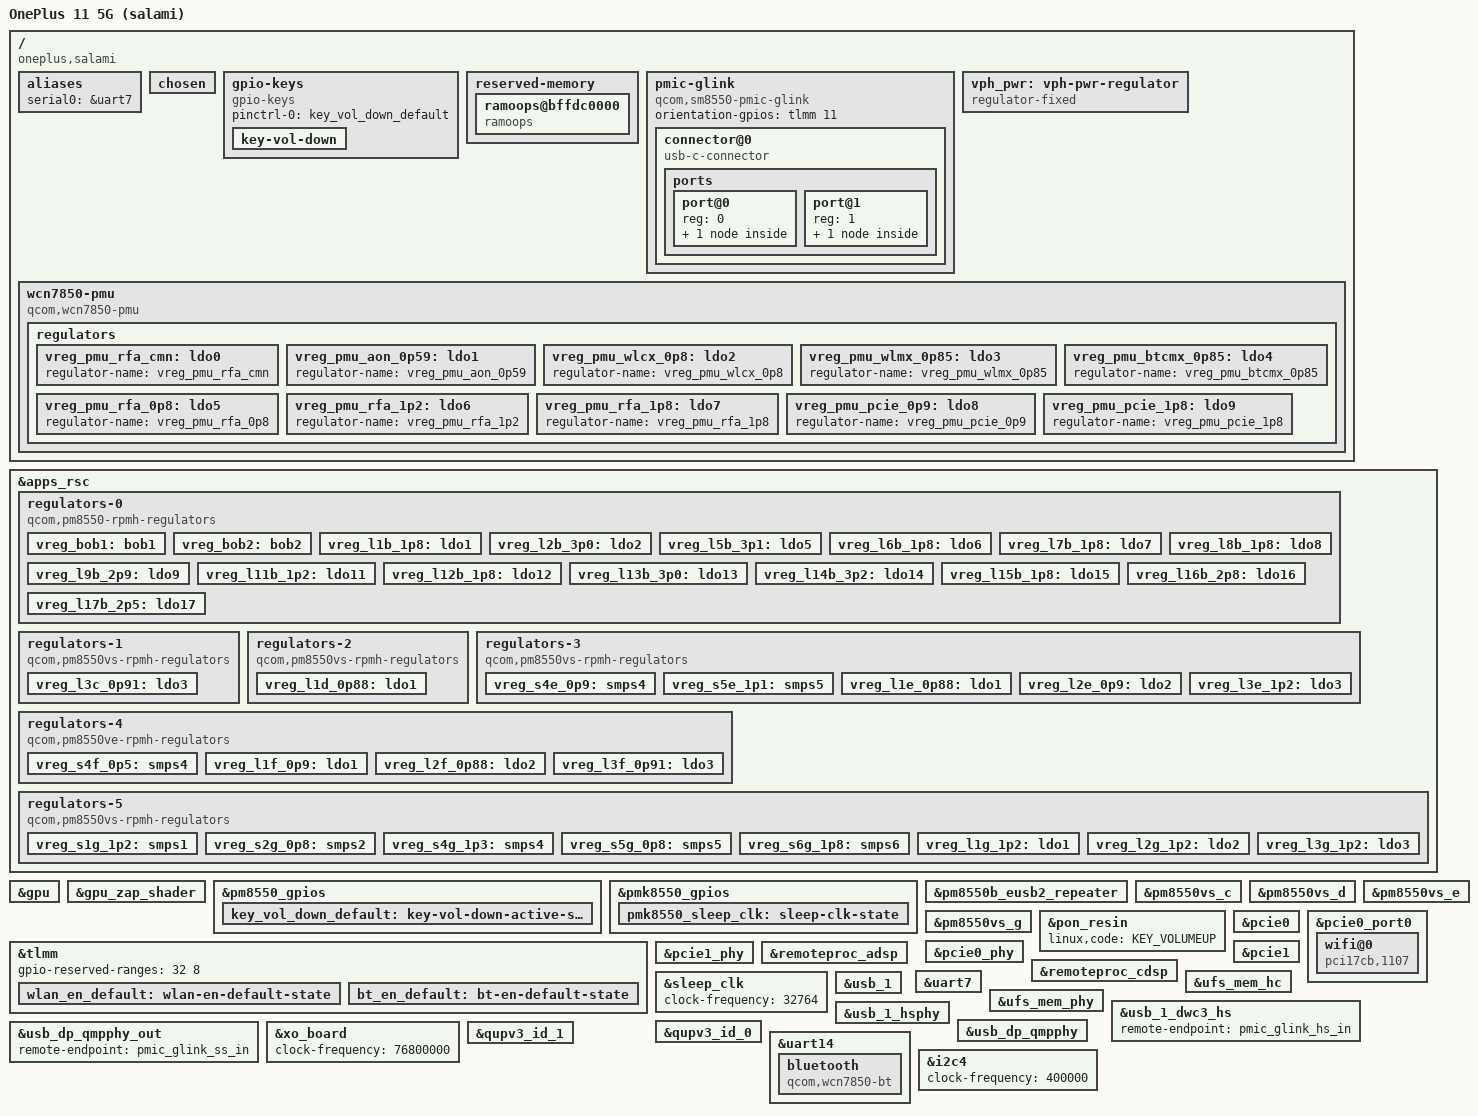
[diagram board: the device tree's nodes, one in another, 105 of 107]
// SPDX-License-Identifier: BSD-3-Clause
/*
 * OnePlus 11 5G (PHB110, codename salami, Qualcomm SM8550/Kalama).
 *
 * Mainline bring-up DTS, modelled after sm8550-mtp.dts with device facts
 * taken from the downstream OnePlus devicetree:
 *   panel   samsung AMB670YF07 CS (reset = TLMM 133)  -- panel driver pending
 *   touch   synaptics S3908 @ i2c4 0x4b (irq TLMM 25, reset TLMM 24) -- pending
 *   vol key PM8550 GPIO6, resin = PMK8550
 */

/dts-v1/;

#include <dt-bindings/input/linux-event-codes.h>
#include <dt-bindings/regulator/qcom,rpmh-regulator.h>
#include "sm8550.dtsi"
#include "pm8550.dtsi"
#include "pm8550b.dtsi"
#define PMK8550VE_SID 5
#include "pm8550ve.dtsi"
#include "pm8550vs.dtsi"
#include "pmk8550.dtsi"

/ {
	model = "OnePlus 11 5G (salami)";
	compatible = "oneplus,salami", "qcom,sm8550";
	chassis-type = "handset";

	qcom,msm-id = <519 0x10000>, <536 0x10000>, <519 0x20000>, <536 0x20000>;
	qcom,board-id = <0x10008 0>;

	aliases {
		serial0 = &uart7;
	};

	chosen {
		stdout-path = "serial0:115200n8";
		bootargs = "earlycon=msm_geni_serial,0x0a9c0000 console=ttyMSM0,115200n8 loglevel=7 keep_bootcon panic=10";
	};

	gpio-keys {
		compatible = "gpio-keys";

		pinctrl-names = "default";
		pinctrl-0 = <&key_vol_down_default>;

		key-vol-down {
			label = "Volume down";
			gpios = <&pm8550_gpios 6 GPIO_ACTIVE_LOW>;
			linux,code = <KEY_VOLUMEDOWN>;
			debounce-interval = <15>;
			wakeup-source;
		};
	};

	reserved-memory {
		/* fixed-address bring-up ramoops: console survives a watchdog/long-press
		 * reboot so it can be read back from /sys/fs/pstore by the stock system */
		ramoops@bffdc0000 {
			compatible = "ramoops";
			reg = <0xb 0xffdc0000 0x0 0x240000>;
			console-size = <0x40000>;
			pmsg-size = <0x200000>;
			no-map;
		};
	};

	pmic-glink {
		compatible = "qcom,sm8550-pmic-glink", "qcom,pmic-glink";
		#address-cells = <1>;
		#size-cells = <0>;
		orientation-gpios = <&tlmm 11 GPIO_ACTIVE_HIGH>;

		connector@0 {
			compatible = "usb-c-connector";
			reg = <0>;
			power-role = "dual";
			data-role = "dual";

			ports {
				#address-cells = <1>;
				#size-cells = <0>;

				port@0 {
					reg = <0>;

					pmic_glink_hs_in: endpoint {
						remote-endpoint = <&usb_1_dwc3_hs>;
					};
				};

				port@1 {
					reg = <1>;

					pmic_glink_ss_in: endpoint {
						remote-endpoint = <&usb_dp_qmpphy_out>;
					};
				};
			};
		};
	};

	vph_pwr: vph-pwr-regulator {
		compatible = "regulator-fixed";
		regulator-name = "vph_pwr";
		regulator-min-microvolt = <3700000>;
		regulator-max-microvolt = <3700000>;

		regulator-always-on;
		regulator-boot-on;
	};

	/* WCN7850 (kiwi) WLAN/BT power sequencing; wlan-en = TLMM 80, bt-en = TLMM 81 */
	wcn7850-pmu {
		compatible = "qcom,wcn7850-pmu";

		pinctrl-names = "default";
		pinctrl-0 = <&wlan_en_default>, <&bt_en_default>, <&pmk8550_sleep_clk>;

		wlan-enable-gpios = <&tlmm 80 GPIO_ACTIVE_HIGH>;
		bt-enable-gpios = <&tlmm 81 GPIO_ACTIVE_HIGH>;

		vdd-supply = <&vreg_s5g_0p8>;
		vddio-supply = <&vreg_l15b_1p8>;
		vddio1p2-supply = <&vreg_l3e_1p2>;
		vddaon-supply = <&vreg_s2g_0p8>;
		vdddig-supply = <&vreg_s4e_0p9>;
		vddrfa1p2-supply = <&vreg_s4g_1p3>;
		vddrfa1p8-supply = <&vreg_s6g_1p8>;

		regulators {
			vreg_pmu_rfa_cmn: ldo0 {
				regulator-name = "vreg_pmu_rfa_cmn";
			};

			vreg_pmu_aon_0p59: ldo1 {
				regulator-name = "vreg_pmu_aon_0p59";
			};

			vreg_pmu_wlcx_0p8: ldo2 {
				regulator-name = "vreg_pmu_wlcx_0p8";
			};

			vreg_pmu_wlmx_0p85: ldo3 {
				regulator-name = "vreg_pmu_wlmx_0p85";
			};

			vreg_pmu_btcmx_0p85: ldo4 {
				regulator-name = "vreg_pmu_btcmx_0p85";
			};

			vreg_pmu_rfa_0p8: ldo5 {
				regulator-name = "vreg_pmu_rfa_0p8";
			};

			vreg_pmu_rfa_1p2: ldo6 {
				regulator-name = "vreg_pmu_rfa_1p2";
			};

			vreg_pmu_rfa_1p8: ldo7 {
				regulator-name = "vreg_pmu_rfa_1p8";
			};

			vreg_pmu_pcie_0p9: ldo8 {
				regulator-name = "vreg_pmu_pcie_0p9";
			};

			vreg_pmu_pcie_1p8: ldo9 {
				regulator-name = "vreg_pmu_pcie_1p8";
			};
		};
	};
};

&apps_rsc {
	regulators-0 {
		compatible = "qcom,pm8550-rpmh-regulators";
		qcom,pmic-id = "b";

		vdd-bob1-supply = <&vph_pwr>;
		vdd-bob2-supply = <&vph_pwr>;
		vdd-l1-l4-l10-supply = <&vreg_s6g_1p8>;
		vdd-l2-l13-l14-supply = <&vreg_bob1>;
		vdd-l3-supply = <&vreg_s4g_1p3>;
		vdd-l5-l16-supply = <&vreg_bob1>;
		vdd-l6-l7-supply = <&vreg_bob1>;
		vdd-l8-l9-supply = <&vreg_bob1>;
		vdd-l11-supply = <&vreg_s4g_1p3>;
		vdd-l12-supply = <&vreg_s6g_1p8>;
		vdd-l15-supply = <&vreg_s6g_1p8>;
		vdd-l17-supply = <&vreg_bob2>;

		vreg_bob1: bob1 {
			regulator-name = "vreg_bob1";
			regulator-min-microvolt = <3296000>;
			regulator-max-microvolt = <3960000>;
			regulator-initial-mode = <RPMH_REGULATOR_MODE_HPM>;
		};

		vreg_bob2: bob2 {
			regulator-name = "vreg_bob2";
			regulator-min-microvolt = <2720000>;
			regulator-max-microvolt = <3960000>;
			regulator-initial-mode = <RPMH_REGULATOR_MODE_HPM>;
		};

		vreg_l1b_1p8: ldo1 {
			regulator-name = "vreg_l1b_1p8";
			regulator-min-microvolt = <1800000>;
			regulator-max-microvolt = <1800000>;
			regulator-initial-mode = <RPMH_REGULATOR_MODE_HPM>;
		};

		vreg_l2b_3p0: ldo2 {
			regulator-name = "vreg_l2b_3p0";
			regulator-min-microvolt = <3008000>;
			regulator-max-microvolt = <3008000>;
			regulator-initial-mode = <RPMH_REGULATOR_MODE_HPM>;
		};

		vreg_l5b_3p1: ldo5 {
			regulator-name = "vreg_l5b_3p1";
			regulator-min-microvolt = <3104000>;
			regulator-max-microvolt = <3104000>;
			regulator-initial-mode = <RPMH_REGULATOR_MODE_HPM>;
		};

		vreg_l6b_1p8: ldo6 {
			regulator-name = "vreg_l6b_1p8";
			regulator-min-microvolt = <1800000>;
			regulator-max-microvolt = <3008000>;
			regulator-initial-mode = <RPMH_REGULATOR_MODE_HPM>;
		};

		vreg_l7b_1p8: ldo7 {
			regulator-name = "vreg_l7b_1p8";
			regulator-min-microvolt = <1800000>;
			regulator-max-microvolt = <3008000>;
			regulator-initial-mode = <RPMH_REGULATOR_MODE_HPM>;
		};

		vreg_l8b_1p8: ldo8 {
			regulator-name = "vreg_l8b_1p8";
			regulator-min-microvolt = <1800000>;
			regulator-max-microvolt = <3008000>;
			regulator-initial-mode = <RPMH_REGULATOR_MODE_HPM>;
		};

		vreg_l9b_2p9: ldo9 {
			regulator-name = "vreg_l9b_2p9";
			regulator-min-microvolt = <2960000>;
			regulator-max-microvolt = <3008000>;
			regulator-initial-mode = <RPMH_REGULATOR_MODE_HPM>;
		};

		vreg_l11b_1p2: ldo11 {
			regulator-name = "vreg_l11b_1p2";
			regulator-min-microvolt = <1200000>;
			regulator-max-microvolt = <1504000>;
			regulator-initial-mode = <RPMH_REGULATOR_MODE_HPM>;
		};

		vreg_l12b_1p8: ldo12 {
			regulator-name = "vreg_l12b_1p8";
			regulator-min-microvolt = <1800000>;
			regulator-max-microvolt = <1800000>;
			regulator-initial-mode = <RPMH_REGULATOR_MODE_HPM>;
		};

		vreg_l13b_3p0: ldo13 {
			regulator-name = "vreg_l13b_3p0";
			regulator-min-microvolt = <3000000>;
			regulator-max-microvolt = <3000000>;
			regulator-initial-mode = <RPMH_REGULATOR_MODE_HPM>;
		};

		vreg_l14b_3p2: ldo14 {
			regulator-name = "vreg_l14b_3p2";
			regulator-min-microvolt = <3200000>;
			regulator-max-microvolt = <3200000>;
			regulator-initial-mode = <RPMH_REGULATOR_MODE_HPM>;
		};

		vreg_l15b_1p8: ldo15 {
			regulator-name = "vreg_l15b_1p8";
			regulator-min-microvolt = <1800000>;
			regulator-max-microvolt = <1800000>;
			regulator-initial-mode = <RPMH_REGULATOR_MODE_HPM>;
		};

		vreg_l16b_2p8: ldo16 {
			regulator-name = "vreg_l16b_2p8";
			regulator-min-microvolt = <2800000>;
			regulator-max-microvolt = <2800000>;
			regulator-initial-mode = <RPMH_REGULATOR_MODE_HPM>;
		};

		vreg_l17b_2p5: ldo17 {
			regulator-name = "vreg_l17b_2p5";
			regulator-min-microvolt = <2504000>;
			regulator-max-microvolt = <2504000>;
			regulator-initial-mode = <RPMH_REGULATOR_MODE_HPM>;
		};
	};

	regulators-1 {
		compatible = "qcom,pm8550vs-rpmh-regulators";
		qcom,pmic-id = "c";

		vdd-l3-supply = <&vreg_s4e_0p9>;

		vreg_l3c_0p91: ldo3 {
			regulator-name = "vreg_l3c_0p9";
			regulator-min-microvolt = <880000>;
			regulator-max-microvolt = <912000>;
			regulator-initial-mode = <RPMH_REGULATOR_MODE_HPM>;
		};
	};

	regulators-2 {
		compatible = "qcom,pm8550vs-rpmh-regulators";
		qcom,pmic-id = "d";

		vdd-l1-supply = <&vreg_s4e_0p9>;

		vreg_l1d_0p88: ldo1 {
			regulator-name = "vreg_l1d_0p88";
			regulator-min-microvolt = <880000>;
			regulator-max-microvolt = <920000>;
			regulator-initial-mode = <RPMH_REGULATOR_MODE_HPM>;
		};
	};

	regulators-3 {
		compatible = "qcom,pm8550vs-rpmh-regulators";
		qcom,pmic-id = "e";

		vdd-l1-supply = <&vreg_s4e_0p9>;
		vdd-l2-supply = <&vreg_s4e_0p9>;
		vdd-l3-supply = <&vreg_s4g_1p3>;
		vdd-s4-supply = <&vph_pwr>;
		vdd-s5-supply = <&vph_pwr>;

		vreg_s4e_0p9: smps4 {
			regulator-name = "vreg_s4e_0p9";
			regulator-min-microvolt = <904000>;
			regulator-max-microvolt = <984000>;
			regulator-initial-mode = <RPMH_REGULATOR_MODE_HPM>;
		};

		vreg_s5e_1p1: smps5 {
			regulator-name = "vreg_s5e_1p1";
			regulator-min-microvolt = <1080000>;
			regulator-max-microvolt = <1120000>;
			regulator-initial-mode = <RPMH_REGULATOR_MODE_HPM>;
		};

		vreg_l1e_0p88: ldo1 {
			regulator-name = "vreg_l1e_0p88";
			regulator-min-microvolt = <880000>;
			regulator-max-microvolt = <880000>;
			regulator-initial-mode = <RPMH_REGULATOR_MODE_HPM>;
		};

		vreg_l2e_0p9: ldo2 {
			regulator-name = "vreg_l2e_0p9";
			regulator-min-microvolt = <904000>;
			regulator-max-microvolt = <970000>;
			regulator-initial-mode = <RPMH_REGULATOR_MODE_HPM>;
		};

		vreg_l3e_1p2: ldo3 {
			regulator-name = "vreg_l3e_1p2";
			regulator-min-microvolt = <1200000>;
			regulator-max-microvolt = <1200000>;
			regulator-initial-mode = <RPMH_REGULATOR_MODE_HPM>;
		};
	};

	regulators-4 {
		compatible = "qcom,pm8550ve-rpmh-regulators";
		qcom,pmic-id = "f";

		vdd-l1-supply = <&vreg_s4e_0p9>;
		vdd-l2-supply = <&vreg_s4e_0p9>;
		vdd-l3-supply = <&vreg_s4e_0p9>;
		vdd-s4-supply = <&vph_pwr>;

		vreg_s4f_0p5: smps4 {
			regulator-name = "vreg_s4f_0p5";
			regulator-min-microvolt = <500000>;
			regulator-max-microvolt = <700000>;
			regulator-initial-mode = <RPMH_REGULATOR_MODE_HPM>;
		};

		vreg_l1f_0p9: ldo1 {
			regulator-name = "vreg_l1f_0p9";
			regulator-min-microvolt = <912000>;
			regulator-max-microvolt = <912000>;
			regulator-initial-mode = <RPMH_REGULATOR_MODE_HPM>;
		};

		vreg_l2f_0p88: ldo2 {
			regulator-name = "vreg_l2f_0p88";
			regulator-min-microvolt = <880000>;
			regulator-max-microvolt = <912000>;
			regulator-initial-mode = <RPMH_REGULATOR_MODE_HPM>;
		};

		vreg_l3f_0p91: ldo3 {
			regulator-name = "vreg_l3f_0p91";
			regulator-min-microvolt = <880000>;
			regulator-max-microvolt = <912000>;
			regulator-initial-mode = <RPMH_REGULATOR_MODE_HPM>;
		};
	};

	regulators-5 {
		compatible = "qcom,pm8550vs-rpmh-regulators";
		qcom,pmic-id = "g";

		vdd-l1-supply = <&vreg_s4g_1p3>;
		vdd-l2-supply = <&vreg_s4g_1p3>;
		vdd-l3-supply = <&vreg_s4g_1p3>;
		vdd-s1-supply = <&vph_pwr>;
		vdd-s2-supply = <&vph_pwr>;
		/* smpg3 does not exist in this device's cmd-db; omit smps3 */
		vdd-s4-supply = <&vph_pwr>;
		vdd-s5-supply = <&vph_pwr>;
		vdd-s6-supply = <&vph_pwr>;

		vreg_s1g_1p2: smps1 {
			regulator-name = "vreg_s1g_1p2";
			regulator-min-microvolt = <1200000>;
			regulator-max-microvolt = <1300000>;
			regulator-initial-mode = <RPMH_REGULATOR_MODE_HPM>;
		};

		vreg_s2g_0p8: smps2 {
			regulator-name = "vreg_s2g_0p8";
			/* stock CNSS PDC: vddaon 激活态 976mV（主线 800mV 欠压导致 AMSS 不启动） */
			regulator-min-microvolt = <976000>;
			regulator-max-microvolt = <976000>;
			regulator-initial-mode = <RPMH_REGULATOR_MODE_HPM>;
		};

		vreg_s4g_1p3: smps4 {
			regulator-name = "vreg_s4g_1p3";
			regulator-min-microvolt = <1200000>;
			regulator-max-microvolt = <1352000>;
			regulator-initial-mode = <RPMH_REGULATOR_MODE_HPM>;
		};

		vreg_s5g_0p8: smps5 {
			regulator-name = "vreg_s5g_0p8";
			/* stock CNSS PDC: vdd 激活态 940mV */
			regulator-min-microvolt = <940000>;
			regulator-max-microvolt = <940000>;
			regulator-initial-mode = <RPMH_REGULATOR_MODE_HPM>;
		};

		vreg_s6g_1p8: smps6 {
			regulator-name = "vreg_s6g_1p8";
			regulator-min-microvolt = <1800000>;
			regulator-max-microvolt = <2000000>;
			regulator-initial-mode = <RPMH_REGULATOR_MODE_HPM>;
		};

		vreg_l1g_1p2: ldo1 {
			regulator-name = "vreg_l1g_1p2";
			regulator-min-microvolt = <1200000>;
			regulator-max-microvolt = <1200000>;
			regulator-initial-mode = <RPMH_REGULATOR_MODE_HPM>;
		};

		vreg_l2g_1p2: ldo2 {
			regulator-name = "vreg_l2g_1p2";
			regulator-min-microvolt = <1200000>;
			regulator-max-microvolt = <1200000>;
			regulator-initial-mode = <RPMH_REGULATOR_MODE_HPM>;
		};

		vreg_l3g_1p2: ldo3 {
			regulator-name = "vreg_l3g_1p2";
			regulator-min-microvolt = <1200000>;
			regulator-max-microvolt = <1200000>;
			regulator-initial-mode = <RPMH_REGULATOR_MODE_HPM>;
		};
	};
};

&gpu {
	status = "okay";
};

&gpu_zap_shader {
	firmware-name = "qcom/sm8550/oneplus/salami/a740_zap.mbn";
};

&pm8550_gpios {
	key_vol_down_default: key-vol-down-active-state {
		pins = "gpio6";
		function = "normal";
		input-enable;
		output-disable;
		bias-pull-up;
		power-source = <1>; /* 1.8 V */
	};
};

&pmk8550_gpios {
	pmk8550_sleep_clk: sleep-clk-state {
		pins = "gpio3";
		function = "func1";
		input-disable;
		output-enable;
		bias-disable;
		power-source = <0>;
	};
};

&tlmm {
	wlan_en_default: wlan-en-default-state {
		pins = "gpio80";
		function = "gpio";
		drive-strength = <8>;
		bias-pull-down;
	};

	bt_en_default: bt-en-default-state {
		pins = "gpio81";
		function = "gpio";
		drive-strength = <16>;
		bias-disable;
	};
};

&pm8550b_eusb2_repeater {
	vdd18-supply = <&vreg_l15b_1p8>;
	vdd3-supply = <&vreg_l5b_3p1>;
};

&pm8550vs_c {
	status = "okay";
};

&pm8550vs_d {
	status = "okay";
};

&pm8550vs_e {
	status = "okay";
};

&pm8550vs_g {
	status = "okay";
};

&pon_resin {
	linux,code = <KEY_VOLUMEUP>;
	status = "okay";
};

&pcie0 {
	wake-gpios = <&tlmm 96 GPIO_ACTIVE_HIGH>;
	perst-gpios = <&tlmm 94 GPIO_ACTIVE_LOW>;

	pinctrl-names = "default";
	pinctrl-0 = <&pcie0_default_state>;

	status = "okay";
};

&pcie0_port0 {
	wifi@0 {
		compatible = "pci17cb,1107";
		reg = <0x10000 0x0 0x0 0x0 0x0>;

		status = "okay";

		vddrfacmn-supply = <&vreg_pmu_rfa_cmn>;
		vddaon-supply = <&vreg_pmu_aon_0p59>;
		vddwlcx-supply = <&vreg_pmu_wlcx_0p8>;
		vddwlmx-supply = <&vreg_pmu_wlmx_0p85>;
		vddrfa0p8-supply = <&vreg_pmu_rfa_0p8>;
		vddrfa1p2-supply = <&vreg_pmu_rfa_1p2>;
		vddrfa1p8-supply = <&vreg_pmu_rfa_1p8>;
		vddpcie0p9-supply = <&vreg_pmu_pcie_0p9>;
		vddpcie1p8-supply = <&vreg_pmu_pcie_1p8>;
	};
};

&pcie0_phy {
	vdda-phy-supply = <&vreg_l1e_0p88>;
	vdda-pll-supply = <&vreg_l3e_1p2>;

	status = "okay";
};

&pcie1 {
	wake-gpios = <&tlmm 99 GPIO_ACTIVE_HIGH>;
	perst-gpios = <&tlmm 97 GPIO_ACTIVE_LOW>;

	pinctrl-names = "default";
	pinctrl-0 = <&pcie1_default_state>;

	status = "okay";
};

&pcie1_phy {
	vdda-phy-supply = <&vreg_l3c_0p91>;
	vdda-pll-supply = <&vreg_l3e_1p2>;
	vdda-qref-supply = <&vreg_l1e_0p88>;

	status = "okay";
};

&remoteproc_adsp {
	firmware-name = "qcom/sm8550/oneplus/salami/adsp.mbn",
			"qcom/sm8550/oneplus/salami/adsp_dtb.mbn";
	status = "okay";
};

&remoteproc_cdsp {
	firmware-name = "qcom/sm8550/oneplus/salami/cdsp.mbn",
			"qcom/sm8550/oneplus/salami/cdsp_dtb.mbn";
	status = "okay";
};

&sleep_clk {
	clock-frequency = <32764>;
};

&tlmm {
	gpio-reserved-ranges = <32 8>;
};

&uart7 {
	status = "okay";
};

&ufs_mem_hc {
	reset-gpios = <&tlmm 210 GPIO_ACTIVE_LOW>;
	vcc-supply = <&vreg_l17b_2p5>;
	vcc-max-microamp = <1300000>;
	vccq-supply = <&vreg_l1g_1p2>;
	vccq-max-microamp = <1200000>;
	vdd-hba-supply = <&vreg_l3g_1p2>;

	status = "okay";
};

&ufs_mem_phy {
	vdda-phy-supply = <&vreg_l1d_0p88>;
	vdda-pll-supply = <&vreg_l3e_1p2>;

	status = "okay";
};

&usb_1 {
	status = "okay";
};

&usb_1_dwc3_hs {
	remote-endpoint = <&pmic_glink_hs_in>;
};

&usb_1_hsphy {
	vdd-supply = <&vreg_l1e_0p88>;
	vdda12-supply = <&vreg_l3e_1p2>;

	phys = <&pm8550b_eusb2_repeater>;

	status = "okay";
};

&usb_dp_qmpphy {
	vdda-phy-supply = <&vreg_l3f_0p91>;
	vdda-pll-supply = <&vreg_l3e_1p2>;

	status = "okay";
};

&usb_dp_qmpphy_out {
	remote-endpoint = <&pmic_glink_ss_in>;
};

&xo_board {
	clock-frequency = <76800000>;
};

/* ---- 批次1: qupv3 包装器（uart14/i2c4 的父总线，必须启用） ---- */
&qupv3_id_0 {
	status = "okay";
};

&qupv3_id_1 {
	status = "okay";
};

/* ---- 批次1: 蓝牙 (WCN7850 BT over uart14 serdev) ---- */
&uart14 {
	status = "okay";

	bluetooth {
		compatible = "qcom,wcn7850-bt";

		/* TODO: 换成 salami 真实 BD 地址（可从 stock /persist 分区提取） */
		local-bd-address = [ 24 00 00 00 5a ad ];

		vddrfacmn-supply = <&vreg_pmu_rfa_cmn>;
		vddaon-supply = <&vreg_pmu_aon_0p59>;
		vddwlcx-supply = <&vreg_pmu_wlcx_0p8>;
		vddwlmx-supply = <&vreg_pmu_wlmx_0p85>;
		vddrfa0p8-supply = <&vreg_pmu_rfa_0p8>;
		vddrfa1p2-supply = <&vreg_pmu_rfa_1p2>;
		vddrfa1p8-supply = <&vreg_pmu_rfa_1p8>;

		max-speed = <3200000>;
	};
};

/* ---- 批次1: 触摸总线 (Synaptics S3908 @0x4B, 驱动后续接入) ---- */
&i2c4 {
	clock-frequency = <400000>;
	status = "okay";
};
